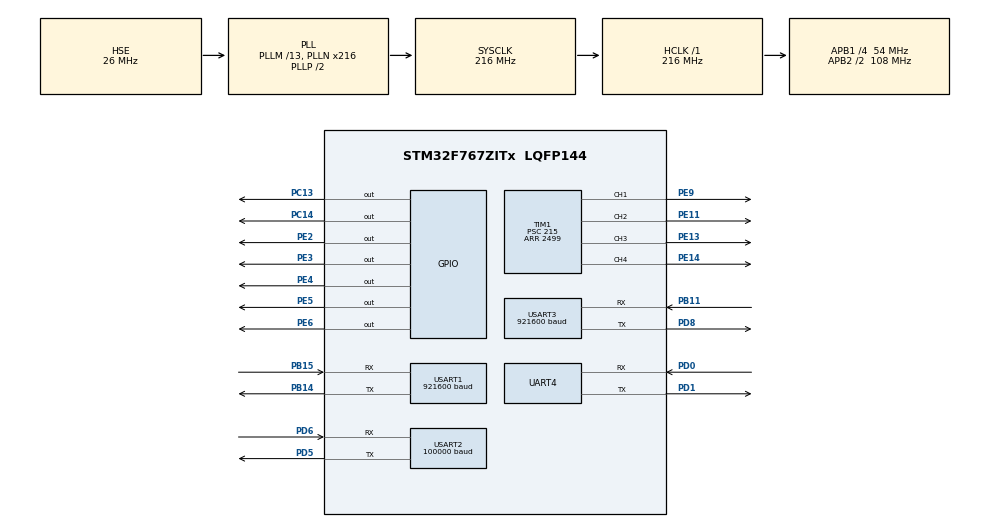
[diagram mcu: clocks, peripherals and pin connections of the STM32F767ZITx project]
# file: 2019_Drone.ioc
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Dma.Request0=USART2_RX
Dma.Request1=USART3_RX
Dma.USART2_RX.0.Direction=DMA_PERIPH_TO_MEMORY
Dma.USART2_RX.0.FIFOMode=DMA_FIFOMODE_DISABLE
Dma.USART2_RX.0.Instance=DMA1_Stream5
Dma.USART2_RX.0.MemDataAlignment=DMA_MDATAALIGN_BYTE
Dma.USART2_RX.0.MemInc=DMA_MINC_ENABLE
Dma.USART2_RX.0.Mode=DMA_CIRCULAR
Dma.USART2_RX.0.PeriphDataAlignment=DMA_PDATAALIGN_BYTE
Dma.USART2_RX.0.PeriphInc=DMA_PINC_DISABLE
Dma.USART2_RX.0.Priority=DMA_PRIORITY_LOW
Dma.USART3_RX.1.Direction=DMA_PERIPH_TO_MEMORY
Dma.USART3_RX.1.FIFOMode=DMA_FIFOMODE_DISABLE
Dma.USART3_RX.1.Instance=DMA1_Stream1
Dma.USART3_RX.1.MemDataAlignment=DMA_MDATAALIGN_BYTE
Dma.USART3_RX.1.MemInc=DMA_MINC_ENABLE
Dma.USART3_RX.1.Mode=DMA_CIRCULAR
Dma.USART3_RX.1.PeriphDataAlignment=DMA_PDATAALIGN_BYTE
Dma.USART3_RX.1.PeriphInc=DMA_PINC_DISABLE
Dma.USART3_RX.1.Priority=DMA_PRIORITY_LOW
Mcu.Family=STM32F7
Mcu.Name=STM32F767ZITx
Mcu.Package=LQFP144
NVIC.DMA1_Stream1_IRQn=true\:0\:0\:false\:false\:true\:false\:true
NVIC.DMA1_Stream5_IRQn=true\:0\:0\:false\:false\:true\:false\:true
NVIC.PriorityGroup=NVIC_PRIORITYGROUP_4
NVIC.TIM6_DAC_IRQn=true\:0\:0\:false\:false\:true\:true\:true
NVIC.TIM7_IRQn=true\:0\:0\:false\:false\:true\:true\:true
NVIC.UART4_IRQn=true\:0\:0\:false\:false\:true\:true\:true
PA13.Mode=Serial_Wire
PA13.Signal=SYS_JTMS-SWDIO
PA14.Mode=Serial_Wire
PA14.Signal=SYS_JTCK-SWCLK
PB11.Mode=Asynchronous
PB11.Signal=USART3_RX
PB14.Mode=Asynchronous
PB14.Signal=USART1_TX
PB15.Mode=Asynchronous
PB15.Signal=USART1_RX
PC13.PinState=GPIO_PIN_SET
PC13.Signal=GPIO_Output
PC14/OSC32_IN.PinState=GPIO_PIN_SET
PC14/OSC32_IN.Signal=GPIO_Output
PD0.Mode=Asynchronous
PD0.Signal=UART4_RX
PD1.Mode=Asynchronous
PD1.Signal=UART4_TX
PD5.Mode=Asynchronous
PD5.Signal=USART2_TX
PD6.Mode=Asynchronous
PD6.Signal=USART2_RX
PD8.Mode=Asynchronous
PD8.Signal=USART3_TX
PE11.Signal=S_TIM1_CH2
PE13.Signal=S_TIM1_CH3
PE14.Signal=S_TIM1_CH4
PE2.PinState=GPIO_PIN_SET
PE2.Signal=GPIO_Output
PE3.PinState=GPIO_PIN_SET
PE3.Signal=GPIO_Output
PE4.PinState=GPIO_PIN_SET
PE4.Signal=GPIO_Output
PE5.PinState=GPIO_PIN_SET
PE5.Signal=GPIO_Output
PE6.Signal=GPIO_Output
PE9.Signal=S_TIM1_CH1
PH0/OSC_IN.Mode=HSE-External-Oscillator
PH0/OSC_IN.Signal=RCC_OSC_IN
PH1/OSC_OUT.Mode=HSE-External-Oscillator
PH1/OSC_OUT.Signal=RCC_OSC_OUT
ProjectManager.HeapSize=0x200
ProjectManager.StackSize=0x4000
ProjectManager.TargetToolchain=EWARM V7
RCC.AHBFreq_Value=216000000
RCC.APB1CLKDivider=RCC_HCLK_DIV4
RCC.APB1Freq_Value=54000000
RCC.APB1TimFreq_Value=108000000
RCC.APB2CLKDivider=RCC_HCLK_DIV2
RCC.APB2Freq_Value=108000000
RCC.APB2TimFreq_Value=216000000
RCC.CortexFreq_Value=216000000
RCC.HCLKFreq_Value=216000000
RCC.HSE_VALUE=26000000
RCC.HSI_VALUE=16000000
RCC.LSE_VALUE=32768
RCC.PLLM=13
RCC.PLLN=216
RCC.PLLSourceVirtual=RCC_PLLSOURCE_HSE
RCC.SYSCLKFreq_VALUE=216000000
RCC.SYSCLKSource=RCC_SYSCLKSOURCE_PLLCLK
RCC.USBFreq_Value=216000000
RCC.VCOOutputFreq_Value=432000000
SH.S_TIM1_CH1.0=TIM1_CH1,PWM Generation1 CH1
SH.S_TIM1_CH2.0=TIM1_CH2,PWM Generation2 CH2
SH.S_TIM1_CH3.0=TIM1_CH3,PWM Generation3 CH3
SH.S_TIM1_CH4.0=TIM1_CH4,PWM Generation4 CH4
TIM1.Channel-PWM\ Generation1\ CH1=TIM_CHANNEL_1
TIM1.Channel-PWM\ Generation2\ CH2=TIM_CHANNEL_2
TIM1.Channel-PWM\ Generation3\ CH3=TIM_CHANNEL_3
TIM1.Channel-PWM\ Generation4\ CH4=TIM_CHANNEL_4
TIM1.Period=2499
TIM1.Prescaler=215
TIM6.Period=999
TIM6.Prescaler=107
TIM7.Period=9999
TIM7.Prescaler=10799
USART1.BaudRate=921600
USART1.VirtualMode-Asynchronous=VM_ASYNC
USART2.BaudRate=100000
USART2.Parity=PARITY_EVEN
USART2.RxPinLevelInvertParam=ADVFEATURE_RXINV_ENABLE
USART2.StopBits=STOPBITS_2
USART2.VirtualMode-Asynchronous=VM_ASYNC
USART2.WordLength=WORDLENGTH_9B
USART3.BaudRate=921600
USART3.VirtualMode-Asynchronous=VM_ASYNC
VP_TIM1_VS_ClockSourceINT.Mode=Internal
VP_TIM6_VS_ClockSourceINT.Mode=Enable_Timer
VP_TIM7_VS_ClockSourceINT.Mode=Enable_Timer
board=custom

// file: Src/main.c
/* USER CODE BEGIN Header */
/**
  ******************************************************************************
  * @file           : main.c
  * @brief          : Main program body
  ******************************************************************************
  * @attention
  *
  * <h2><center>&copy; Copyright (c) 2019 STMicroelectronics.
  * All rights reserved.</center></h2>
  *
  * This software component is licensed by ST under BSD 3-Clause license,
  * the "License"; You may not use this file except in compliance with the
  * License. You may obtain a copy of the License at:
  *                        opensource.org/licenses/BSD-3-Clause
  *
  ******************************************************************************
  */
/* USER CODE END Header */

#include "main.h"
#include "dma.h"
#include "tim.h"
#include "usart.h"
#include "gpio.h"

/* USER CODE BEGIN Includes */
#include "headers.h"
/* USER CODE END Includes */

/* USER CODE BEGIN PV */
_SBUS SBUS;
_SENSOR SENSOR;
_RPY RPY;
_GAIN GAIN;
/* USER CODE END PV */

void SystemClock_Config(void);

int main(void)
{

  /* MCU Configuration--------------------------------------------------------*/

  /* Reset of all peripherals, Initializes the Flash interface and the Systick. */
  HAL_Init();

  /* Configure the system clock */
  SystemClock_Config();

  /* Initialize all configured peripherals */
  MX_GPIO_Init();
  MX_DMA_Init();
  MX_TIM1_Init();
  MX_TIM6_Init();
  MX_TIM7_Init();
  MX_USART1_UART_Init();
  MX_USART2_UART_Init();
  MX_USART3_UART_Init();
  MX_UART4_Init();
  /* USER CODE BEGIN 2 */

  Initialize();

  /* USER CODE END 2 */

  /* Infinite loop */
  /* USER CODE BEGIN WHILE */
  while (1)
  {
//    Sensor_read();
    /* USER CODE END WHILE */

  }
}

void SystemClock_Config(void)
{
  RCC_OscInitTypeDef RCC_OscInitStruct = {0};
  RCC_ClkInitTypeDef RCC_ClkInitStruct = {0};
  RCC_PeriphCLKInitTypeDef PeriphClkInitStruct = {0};

  /** Configure the main internal regulator output voltage
  */
  __HAL_RCC_PWR_CLK_ENABLE();
  __HAL_PWR_VOLTAGESCALING_CONFIG(PWR_REGULATOR_VOLTAGE_SCALE1);
  /** Initializes the CPU, AHB and APB busses clocks
  */
  RCC_OscInitStruct.OscillatorType = RCC_OSCILLATORTYPE_HSE;
  RCC_OscInitStruct.HSEState = RCC_HSE_ON;
  RCC_OscInitStruct.PLL.PLLState = RCC_PLL_ON;
  RCC_OscInitStruct.PLL.PLLSource = RCC_PLLSOURCE_HSE;
  RCC_OscInitStruct.PLL.PLLM = 13;
  RCC_OscInitStruct.PLL.PLLN = 216;
  RCC_OscInitStruct.PLL.PLLP = RCC_PLLP_DIV2;
  RCC_OscInitStruct.PLL.PLLQ = 2;
  if (HAL_RCC_OscConfig(&RCC_OscInitStruct) != HAL_OK)
  {
    Error_Handler();
  }
  /** Activate the Over-Drive mode
  */
  if (HAL_PWREx_EnableOverDrive() != HAL_OK)
  {
    Error_Handler();
  }
  /** Initializes the CPU, AHB and APB busses clocks
  */
  RCC_ClkInitStruct.ClockType = RCC_CLOCKTYPE_HCLK|RCC_CLOCKTYPE_SYSCLK
                              |RCC_CLOCKTYPE_PCLK1|RCC_CLOCKTYPE_PCLK2;
  RCC_ClkInitStruct.SYSCLKSource = RCC_SYSCLKSOURCE_PLLCLK;
  RCC_ClkInitStruct.AHBCLKDivider = RCC_SYSCLK_DIV1;
  RCC_ClkInitStruct.APB1CLKDivider = RCC_HCLK_DIV4;
  RCC_ClkInitStruct.APB2CLKDivider = RCC_HCLK_DIV2;

  if (HAL_RCC_ClockConfig(&RCC_ClkInitStruct, FLASH_LATENCY_7) != HAL_OK)
  {
    Error_Handler();
  }
  PeriphClkInitStruct.PeriphClockSelection = RCC_PERIPHCLK_USART1|RCC_PERIPHCLK_USART2
                              |RCC_PERIPHCLK_USART3|RCC_PERIPHCLK_UART4;
  PeriphClkInitStruct.Usart1ClockSelection = RCC_USART1CLKSOURCE_PCLK2;
  PeriphClkInitStruct.Usart2ClockSelection = RCC_USART2CLKSOURCE_PCLK1;
  PeriphClkInitStruct.Usart3ClockSelection = RCC_USART3CLKSOURCE_PCLK1;
  PeriphClkInitStruct.Uart4ClockSelection = RCC_UART4CLKSOURCE_PCLK1;
  if (HAL_RCCEx_PeriphCLKConfig(&PeriphClkInitStruct) != HAL_OK)
  {
    Error_Handler();
  }
}

/* USER CODE BEGIN 4 */
#ifdef __GNUC__
/* With GCC, small printf (option LD Linker->Libraries->Small printf
   set to 'Yes') calls __io_putchar() */
#define PUTCHAR_PROTOTYPE int __io_putchar(int ch)
#else
#define PUTCHAR_PROTOTYPE int fputc(int ch, FILE *f)
#endif /* __GNUC__ */

PUTCHAR_PROTOTYPE
{
  /* Place your implementation of fputc here */
  /* e.g. write a character to the USART3 and Loop until the end of transmission */
  HAL_UART_Transmit(&huart1, (uint8_t *)&ch, 1, 0xFFFF);

  return ch;
}
/* USER CODE END 4 */

void Error_Handler(void)
{
}

/************************ (C) COPYRIGHT STMicroelectronics *****END OF FILE****/
